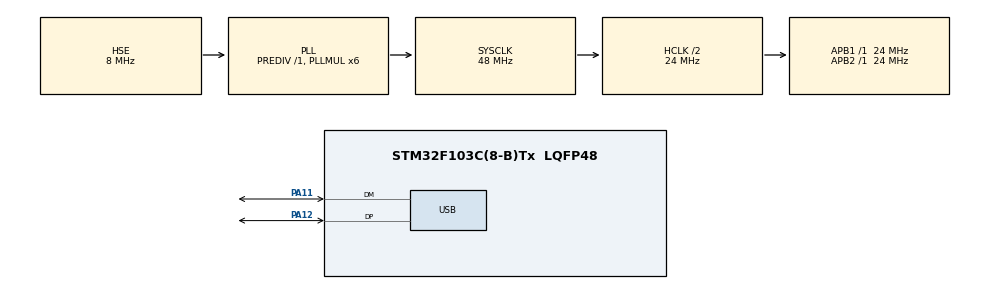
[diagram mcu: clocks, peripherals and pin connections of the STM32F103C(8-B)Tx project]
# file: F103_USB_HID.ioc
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Mcu.Family=STM32F1
Mcu.Name=STM32F103C(8-B)Tx
Mcu.Package=LQFP48
NVIC.PriorityGroup=NVIC_PRIORITYGROUP_4
NVIC.USB_LP_CAN1_RX0_IRQn=true\:1\:0\:true\:false\:true\:false\:true
PA11.Mode=Device
PA11.Signal=USB_DM
PA12.Mode=Device
PA12.Signal=USB_DP
PA13.Mode=Serial_Wire
PA13.Signal=SYS_JTMS-SWDIO
PA14.Mode=Serial_Wire
PA14.Signal=SYS_JTCK-SWCLK
PD0-OSC_IN.Mode=HSE-External-Oscillator
PD0-OSC_IN.Signal=RCC_OSC_IN
PD1-OSC_OUT.Mode=HSE-External-Oscillator
PD1-OSC_OUT.Signal=RCC_OSC_OUT
ProjectManager.HeapSize=0x200
ProjectManager.StackSize=0x400
ProjectManager.TargetToolchain=EWARM V8
RCC.AHBCLKDivider=RCC_SYSCLK_DIV2
RCC.AHBFreq_Value=24000000
RCC.APB1Freq_Value=24000000
RCC.APB1TimFreq_Value=24000000
RCC.APB2Freq_Value=24000000
RCC.APB2TimFreq_Value=24000000
RCC.HCLKFreq_Value=24000000
RCC.PLLMUL=RCC_PLL_MUL6
RCC.SYSCLKFreq_VALUE=48000000
RCC.SYSCLKSource=RCC_SYSCLKSOURCE_PLLCLK
RCC.USBFreq_Value=48000000
USB_DEVICE.CLASS_NAME_FS=HID
USB_DEVICE.VirtualMode=Hid
USB_DEVICE.VirtualModeFS=Hid_FS
VP_USB_DEVICE_VS_USB_DEVICE_HID_FS.Mode=HID_FS
board=custom

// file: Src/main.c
/* USER CODE BEGIN Header */
/**
  ******************************************************************************
  * @file           : main.c
  * @brief          : Main program body
  ******************************************************************************
  * @attention
  *
  * <h2><center>&copy; Copyright (c) 2019 STMicroelectronics.
  * All rights reserved.</center></h2>
  *
  * This software component is licensed by ST under Ultimate Liberty license
  * SLA0044, the "License"; You may not use this file except in compliance with
  * the License. You may obtain a copy of the License at:
  *                             www.st.com/SLA0044
  *
  ******************************************************************************
  */
/* USER CODE END Header */

#include "main.h"
#include "usb_device.h"

/* USER CODE BEGIN Includes */
#include "usbd_hid.h"
/* USER CODE END Includes */

void SystemClock_Config(void);
static void MX_GPIO_Init(void);

/* USER CODE BEGIN 0 */

extern USBD_HandleTypeDef hUsbDeviceFS;
#define BUTTON_REPORT_SIZE 8
#define INTERVAL 20

enum holdrelease {HOLD=0, RELEASE=1};
enum specbutton {LCTRL=0x00, LSHIFT=0x02, LALT=0x04, LMETA=0x08, RCTRL=0x10, RSHIFT=0x20, RALT=0x40, RMETA=0x80};
enum buttons1 {ENTER=0x28,ESC,BACKSPACE,TAB,SPACE,MINUS,EQUAL,LEFTBRACE,RIGHTBRACE,BACKSLASH,HASHTILDE,SEMICOLON,
      APOSTROPHE,GRAVE,COMMA,DOT,SLASH,CAPSLOCK,F1,F2,F3,F4,F5,F6,F7,F8,F9,F10,F11,F12,SYSRQ,SCROLLLOCK,PAUSE,INSERT,
      HOME,PAGEUP,DELETE,END,PAGEDOWN,RIGHT,LEFT,DOWN,UP,NUMLOCK};

uint8_t button_report[BUTTON_REPORT_SIZE] = {0};

#define CLICK_REPORT_SIZE 5
uint8_t click_report[CLICK_REPORT_SIZE] = {0};

void HID_CursorMove(int8_t x, int8_t y)
{
  // [1] - x -right, [2] - y - down
  click_report[1] = x;
  click_report[2] = y;
  USBD_HID_SendReport(&hUsbDeviceFS, click_report, CLICK_REPORT_SIZE);
}

uint8_t HID_GetScanCode(char button)
{
  uint8_t code = 0x00;

  if (button >= 0x61 && button <= 0x7A)
  {
    code = button - 93;
  }
  else
  if (button >= 0x31 && button <= 0x39)
  {
    code = button - 19;
  }
  else
  if (button == 0x30)
    code = 0x27;
  else
  if (button == ' ')
    code = 0x2C;
  return code;
}

void HID_SendSpecButtonData(uint8_t scancode, uint8_t release)
{
  button_report[0] = scancode;
  USBD_HID_SendReport(&hUsbDeviceFS, button_report, BUTTON_REPORT_SIZE);
  HAL_Delay(INTERVAL);
  button_report[0] = 0;
  if (release)
  {
    USBD_HID_SendReport(&hUsbDeviceFS, button_report, BUTTON_REPORT_SIZE);
    HAL_Delay(INTERVAL);
  }
}

void HID_SendButtonData(uint8_t scancode, uint8_t release)
{
  button_report[2] = scancode;
  USBD_HID_SendReport(&hUsbDeviceFS, button_report, BUTTON_REPORT_SIZE);
  HAL_Delay(INTERVAL);
  button_report[2] = 0;
  if (release)
  {
    USBD_HID_SendReport(&hUsbDeviceFS, button_report, BUTTON_REPORT_SIZE);
    HAL_Delay(INTERVAL);
  }
}

void HID_SendCombo(uint8_t scancodespec, uint8_t button)
{
  button_report[0] = scancodespec;
  button_report[2] = HID_GetScanCode(button);
  USBD_HID_SendReport(&hUsbDeviceFS, button_report, BUTTON_REPORT_SIZE);
  HAL_Delay(INTERVAL);
  button_report[0] = 0;
  button_report[2] = 0;
  USBD_HID_SendReport(&hUsbDeviceFS, button_report, BUTTON_REPORT_SIZE);
  HAL_Delay(INTERVAL);
}

void HID_WriteString(uint8_t * str)
{
  uint8_t scancode = 0;
  while (*str)
  {
    scancode = HID_GetScanCode(str[0]);
    HID_SendButtonData(scancode, RELEASE);
    str++;
  }
}

#define STEPSIZE 10
#define DELAYSTEPS 15
#define ITERATIONS 5

/* USER CODE END 0 */

int main(void)
{

  /* MCU Configuration--------------------------------------------------------*/

  /* Reset of all peripherals, Initializes the Flash interface and the Systick. */
  HAL_Init();

  /* Configure the system clock */
  SystemClock_Config();

  /* Initialize all configured peripherals */
  MX_GPIO_Init();
  MX_USB_DEVICE_Init();
  /* USER CODE BEGIN 2 */
  HAL_Delay(1000);
  /* USER CODE END 2 */

  /* Infinite loop */
  while (1)
  {

    /* USER CODE BEGIN 3 */
#ifdef USE_MOUSE
    /*
    for (int i = 0; i < ITERATIONS; i++)
    {
      HID_CursorMove(STEPSIZE,STEPSIZE);
      HAL_Delay(DELAYSTEPS);
    }
    for (int i = 0; i < ITERATIONS; i++)
    {
      HID_CursorMove(-STEPSIZE,STEPSIZE);
      HAL_Delay(DELAYSTEPS);
    }
    for (int i = 0; i < ITERATIONS; i++)
    {
      HID_CursorMove(-STEPSIZE,-STEPSIZE);
      HAL_Delay(DELAYSTEPS);
    }
    for (int i = 0; i < ITERATIONS; i++)
    {
      HID_CursorMove(STEPSIZE,-STEPSIZE);
      HAL_Delay(DELAYSTEPS);
    }*/
    /*HID_CursorMove(rand() % 200 - 100,rand() % 200 - 100);
    HAL_Delay(1000 + rand() % 4000);*/
    int8_t x = rand() % 255 - 127;
    int8_t y = rand() % 255 - 127;
    int step_num = 5;
    int8_t stepx = x / step_num;
    int8_t stepy = y / step_num;
    for (int i = 0; i < step_num; i++)
    {
      HID_CursorMove(i*stepx,i*stepy);
      HAL_Delay(100);
    }
#else
    HID_SendCombo(LMETA, 'r');
    HID_WriteString("notepad");
    HID_SendButtonData(ENTER,RELEASE);
    HAL_Delay(100);
    HID_WriteString("nu privet   kak dela  tebya vzlomali asdasdasdasdasds");
    HAL_Delay(100);
#endif

  }
  /* USER CODE END 3 */
}

void SystemClock_Config(void)
{
  RCC_OscInitTypeDef RCC_OscInitStruct = {0};
  RCC_ClkInitTypeDef RCC_ClkInitStruct = {0};
  RCC_PeriphCLKInitTypeDef PeriphClkInit = {0};

  /** Initializes the CPU, AHB and APB busses clocks
  */
  RCC_OscInitStruct.OscillatorType = RCC_OSCILLATORTYPE_HSE;
  RCC_OscInitStruct.HSEState = RCC_HSE_ON;
  RCC_OscInitStruct.HSEPredivValue = RCC_HSE_PREDIV_DIV1;
  RCC_OscInitStruct.HSIState = RCC_HSI_ON;
  RCC_OscInitStruct.PLL.PLLState = RCC_PLL_ON;
  RCC_OscInitStruct.PLL.PLLSource = RCC_PLLSOURCE_HSE;
  RCC_OscInitStruct.PLL.PLLMUL = RCC_PLL_MUL6;
  if (HAL_RCC_OscConfig(&RCC_OscInitStruct) != HAL_OK)
  {
    Error_Handler();
  }
  /** Initializes the CPU, AHB and APB busses clocks
  */
  RCC_ClkInitStruct.ClockType = RCC_CLOCKTYPE_HCLK|RCC_CLOCKTYPE_SYSCLK
                              |RCC_CLOCKTYPE_PCLK1|RCC_CLOCKTYPE_PCLK2;
  RCC_ClkInitStruct.SYSCLKSource = RCC_SYSCLKSOURCE_PLLCLK;
  RCC_ClkInitStruct.AHBCLKDivider = RCC_SYSCLK_DIV2;
  RCC_ClkInitStruct.APB1CLKDivider = RCC_HCLK_DIV1;
  RCC_ClkInitStruct.APB2CLKDivider = RCC_HCLK_DIV1;

  if (HAL_RCC_ClockConfig(&RCC_ClkInitStruct, FLASH_LATENCY_1) != HAL_OK)
  {
    Error_Handler();
  }
  PeriphClkInit.PeriphClockSelection = RCC_PERIPHCLK_USB;
  PeriphClkInit.UsbClockSelection = RCC_USBCLKSOURCE_PLL;
  if (HAL_RCCEx_PeriphCLKConfig(&PeriphClkInit) != HAL_OK)
  {
    Error_Handler();
  }
}

static void MX_GPIO_Init(void)
{

  /* GPIO Ports Clock Enable */
  __HAL_RCC_GPIOD_CLK_ENABLE();
  __HAL_RCC_GPIOA_CLK_ENABLE();

}

void Error_Handler(void)
{
}

/************************ (C) COPYRIGHT STMicroelectronics *****END OF FILE****/
